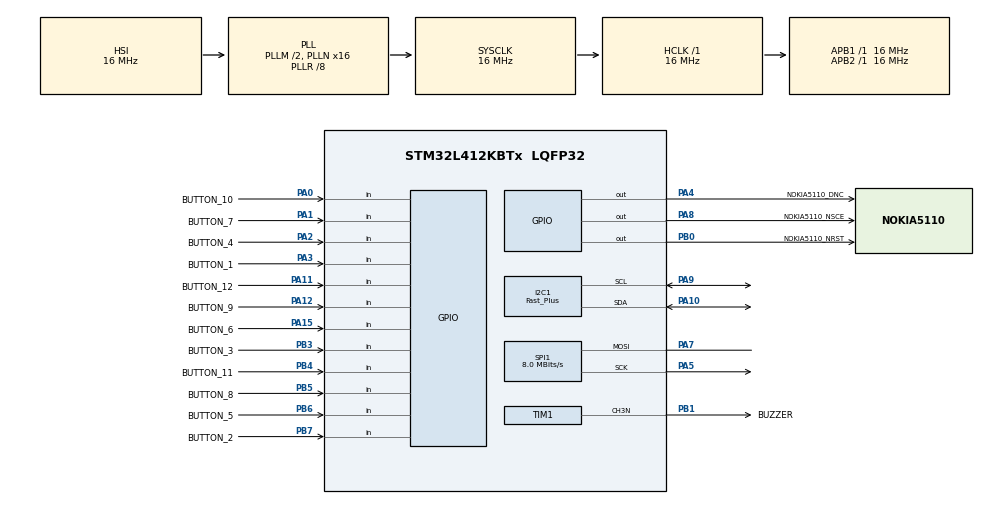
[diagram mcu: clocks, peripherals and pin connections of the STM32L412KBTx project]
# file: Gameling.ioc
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I2C1.I2C_Speed_Mode=I2C_Fast_Plus
I2C1.Timing=0x00000107
Mcu.Family=STM32L4
Mcu.Name=STM32L412KBTx
Mcu.Package=LQFP32
NVIC.PriorityGroup=NVIC_PRIORITYGROUP_4
PA0-CK_IN.GPIO_Label=BUTTON_10
PA0-CK_IN.GPIO_PuPd=GPIO_PULLUP
PA0-CK_IN.Signal=GPIO_Input
PA1.GPIO_Label=BUTTON_7
PA1.GPIO_PuPd=GPIO_PULLUP
PA1.Signal=GPIO_Input
PA10.Mode=I2C
PA10.Signal=I2C1_SDA
PA11.GPIO_Label=BUTTON_12
PA11.GPIO_PuPd=GPIO_PULLUP
PA11.Signal=GPIO_Input
PA12.GPIO_Label=BUTTON_9
PA12.GPIO_PuPd=GPIO_PULLUP
PA12.Signal=GPIO_Input
PA13\ (JTMS/SWDIO).Mode=Serial_Wire
PA13\ (JTMS/SWDIO).Signal=SYS_JTMS-SWDIO
PA14\ (JTCK/SWCLK).Mode=Serial_Wire
PA14\ (JTCK/SWCLK).Signal=SYS_JTCK-SWCLK
PA15\ (JTDI).GPIO_Label=BUTTON_6
PA15\ (JTDI).GPIO_PuPd=GPIO_PULLUP
PA15\ (JTDI).Signal=GPIO_Input
PA2.GPIO_Label=BUTTON_4
PA2.GPIO_PuPd=GPIO_PULLUP
PA2.Signal=GPIO_Input
PA3.GPIO_Label=BUTTON_1
PA3.GPIO_PuPd=GPIO_PULLUP
PA3.Signal=GPIO_Input
PA4.GPIO_Label=NOKIA5110_DNC
PA4.GPIO_PuPd=GPIO_PULLDOWN
PA4.Signal=GPIO_Output
PA5.GPIO_PuPd=GPIO_PULLDOWN
PA5.Mode=Simplex_Bidirectional_Master
PA5.Signal=SPI1_SCK
PA7.GPIO_PuPd=GPIO_PULLDOWN
PA7.Mode=Simplex_Bidirectional_Master
PA7.Signal=SPI1_MOSI
PA8.GPIO_Label=NOKIA5110_NSCE
PA8.GPIO_PuPd=GPIO_PULLDOWN
PA8.Signal=GPIO_Output
PA9.Mode=I2C
PA9.Signal=I2C1_SCL
PB0.GPIO_Label=NOKIA5110_NRST
PB0.GPIO_PuPd=GPIO_PULLUP
PB0.Signal=GPIO_Output
PB1.GPIO_Label=BUZZER
PB1.Mode=PWM Generation3 CH3N
PB1.Signal=TIM1_CH3N
PB3\ (JTDO/TRACESWO).GPIO_Label=BUTTON_3
PB3\ (JTDO/TRACESWO).GPIO_PuPd=GPIO_PULLUP
PB3\ (JTDO/TRACESWO).Signal=GPIO_Input
PB4\ (NJTRST).GPIO_Label=BUTTON_11
PB4\ (NJTRST).GPIO_PuPd=GPIO_PULLUP
PB4\ (NJTRST).Signal=GPIO_Input
PB5.GPIO_Label=BUTTON_8
PB5.GPIO_PuPd=GPIO_PULLUP
PB5.Signal=GPIO_Input
PB6.GPIO_Label=BUTTON_5
PB6.GPIO_PuPd=GPIO_PULLUP
PB6.Signal=GPIO_Input
PB7.GPIO_Label=BUTTON_2
PB7.GPIO_PuPd=GPIO_PULLUP
PB7.Signal=GPIO_Input
ProjectManager.HeapSize=0x200
ProjectManager.StackSize=0x400
ProjectManager.TargetToolchain=SW4STM32
RCC.ADCFreq_Value=16000000
RCC.AHBFreq_Value=16000000
RCC.APB1Freq_Value=16000000
RCC.APB1TimFreq_Value=16000000
RCC.APB2Freq_Value=16000000
RCC.APB2TimFreq_Value=16000000
RCC.CortexFreq_Value=16000000
RCC.HCLKFreq_Value=16000000
RCC.HSE_VALUE=8000000
RCC.HSI48_VALUE=48000000
RCC.HSI_VALUE=16000000
RCC.LSE_VALUE=32768
RCC.MSI_VALUE=4000000
RCC.PLLM=2
RCC.PLLN=16
RCC.PLLR=RCC_PLLR_DIV8
RCC.PLLSourceVirtual=RCC_PLLSOURCE_HSI
RCC.SYSCLKFreq_VALUE=16000000
RCC.SYSCLKSource=RCC_SYSCLKSOURCE_PLLCLK
RCC.USBFreq_Value=4000000
RCC.VCOOutputFreq_Value=128000000
SPI1.CLKPhase=SPI_PHASE_1EDGE
SPI1.CLKPolarity=SPI_POLARITY_LOW
SPI1.CalculateBaudRate=8.0 MBits/s
SPI1.DataSize=SPI_DATASIZE_8BIT
SPI1.Direction=SPI_DIRECTION_1LINE
SPI1.Mode=SPI_MODE_MASTER
SPI1.VirtualType=VM_MASTER
TIM1.Channel-PWM\ Generation3\ CH3N=TIM_CHANNEL_3
TIM1.Prescaler=32-1
board=custom

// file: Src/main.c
/**
  ******************************************************************************
  * @file           : main.c
  * @brief          : Main program body
  ******************************************************************************
  ** This notice applies to any and all portions of this file
  * that are not between comment pairs USER CODE BEGIN and
  * USER CODE END. Other portions of this file, whether
  * inserted by the user or by software development tools
  * are owned by their respective copyright owners.
  *
  * COPYRIGHT(c) 2019 STMicroelectronics
  *
  * Redistribution and use in source and binary forms, with or without modification,
  * are permitted provided that the following conditions are met:
  *   1. Redistributions of source code must retain the above copyright notice,
  *      this list of conditions and the following disclaimer.
  *   2. Redistributions in binary form must reproduce the above copyright notice,
  *      this list of conditions and the following disclaimer in the documentation
  *      and/or other materials provided with the distribution.
  *   3. Neither the name of STMicroelectronics nor the names of its contributors
  *      may be used to endorse or promote products derived from this software
  *      without specific prior written permission.
  *
  * THIS SOFTWARE IS PROVIDED BY THE COPYRIGHT HOLDERS AND CONTRIBUTORS "AS IS"
  * AND ANY EXPRESS OR IMPLIED WARRANTIES, INCLUDING, BUT NOT LIMITED TO, THE
  * IMPLIED WARRANTIES OF MERCHANTABILITY AND FITNESS FOR A PARTICULAR PURPOSE ARE
  * DISCLAIMED. IN NO EVENT SHALL THE COPYRIGHT HOLDER OR CONTRIBUTORS BE LIABLE
  * FOR ANY DIRECT, INDIRECT, INCIDENTAL, SPECIAL, EXEMPLARY, OR CONSEQUENTIAL
  * DAMAGES (INCLUDING, BUT NOT LIMITED TO, PROCUREMENT OF SUBSTITUTE GOODS OR
  * SERVICES; LOSS OF USE, DATA, OR PROFITS; OR BUSINESS INTERRUPTION) HOWEVER
  * CAUSED AND ON ANY THEORY OF LIABILITY, WHETHER IN CONTRACT, STRICT LIABILITY,
  * OR TORT (INCLUDING NEGLIGENCE OR OTHERWISE) ARISING IN ANY WAY OUT OF THE USE
  * OF THIS SOFTWARE, EVEN IF ADVISED OF THE POSSIBILITY OF SUCH DAMAGE.
  *
  ******************************************************************************
  */
#include "main.h"
#include "stm32l4xx_hal.h"
#include "i2c.h"
#include "spi.h"
#include "tim.h"
#include "gpio.h"

/* USER CODE BEGIN Includes */
#include "application.h"
/* USER CODE END Includes */

/* USER CODE BEGIN PV */
/* Private variables ---------------------------------------------------------*/

/* USER CODE END PV */

void SystemClock_Config(void);

/* USER CODE BEGIN PFP */
/* Private function prototypes -----------------------------------------------*/

/* USER CODE END PFP */

int main(void)
{

  /* MCU Configuration----------------------------------------------------------*/

  /* Reset of all peripherals, Initializes the Flash interface and the Systick. */
  HAL_Init();

  /* Configure the system clock */
  SystemClock_Config();

  /* Initialize all configured peripherals */
  MX_GPIO_Init();
  MX_I2C1_Init();
  MX_SPI1_Init();
  MX_TIM1_Init();
  /* USER CODE BEGIN 2 */
  application_main();
  /* USER CODE END 2 */

  /* Infinite loop */
  while (1)
  {

  }

}

void SystemClock_Config(void)
{

  RCC_OscInitTypeDef RCC_OscInitStruct;
  RCC_ClkInitTypeDef RCC_ClkInitStruct;
  RCC_PeriphCLKInitTypeDef PeriphClkInit;

    /**Configure the main internal regulator output voltage
    */
  if (HAL_PWREx_ControlVoltageScaling(PWR_REGULATOR_VOLTAGE_SCALE1) != HAL_OK)
  {
    _Error_Handler(__FILE__, __LINE__);
  }

    /**Initializes the CPU, AHB and APB busses clocks
    */
  RCC_OscInitStruct.OscillatorType = RCC_OSCILLATORTYPE_HSI;
  RCC_OscInitStruct.HSIState = RCC_HSI_ON;
  RCC_OscInitStruct.HSICalibrationValue = 64;
  RCC_OscInitStruct.PLL.PLLState = RCC_PLL_ON;
  RCC_OscInitStruct.PLL.PLLSource = RCC_PLLSOURCE_HSI;
  RCC_OscInitStruct.PLL.PLLM = 2;
  RCC_OscInitStruct.PLL.PLLN = 16;
  RCC_OscInitStruct.PLL.PLLQ = RCC_PLLQ_DIV2;
  RCC_OscInitStruct.PLL.PLLR = RCC_PLLR_DIV8;
  if (HAL_RCC_OscConfig(&RCC_OscInitStruct) != HAL_OK)
  {
    _Error_Handler(__FILE__, __LINE__);
  }

    /**Initializes the CPU, AHB and APB busses clocks
    */
  RCC_ClkInitStruct.ClockType = RCC_CLOCKTYPE_HCLK|RCC_CLOCKTYPE_SYSCLK
                              |RCC_CLOCKTYPE_PCLK1|RCC_CLOCKTYPE_PCLK2;
  RCC_ClkInitStruct.SYSCLKSource = RCC_SYSCLKSOURCE_PLLCLK;
  RCC_ClkInitStruct.AHBCLKDivider = RCC_SYSCLK_DIV1;
  RCC_ClkInitStruct.APB1CLKDivider = RCC_HCLK_DIV1;
  RCC_ClkInitStruct.APB2CLKDivider = RCC_HCLK_DIV1;

  if (HAL_RCC_ClockConfig(&RCC_ClkInitStruct, FLASH_LATENCY_0) != HAL_OK)
  {
    _Error_Handler(__FILE__, __LINE__);
  }

  PeriphClkInit.PeriphClockSelection = RCC_PERIPHCLK_I2C1;
  PeriphClkInit.I2c1ClockSelection = RCC_I2C1CLKSOURCE_PCLK1;
  if (HAL_RCCEx_PeriphCLKConfig(&PeriphClkInit) != HAL_OK)
  {
    _Error_Handler(__FILE__, __LINE__);
  }

    /**Configure the Systick interrupt time
    */
  HAL_SYSTICK_Config(HAL_RCC_GetHCLKFreq()/1000);

    /**Configure the Systick
    */
  HAL_SYSTICK_CLKSourceConfig(SYSTICK_CLKSOURCE_HCLK);

  /* SysTick_IRQn interrupt configuration */
  HAL_NVIC_SetPriority(SysTick_IRQn, 0, 0);
}

void _Error_Handler(char *file, int line)
{
  while(1)
  {
  }
}

/************************ (C) COPYRIGHT STMicroelectronics *****END OF FILE****/
